# iospear320 register map
Registers are 32-bit, access not given, no defined reset value unless marked. A register's access mark holds for its fields unless they carry their own. Addresses are absolute; registers are grouped by the start of their names; [hi:lo] are bit positions; {n}, {i} and the like mark numbered series.

## MAC
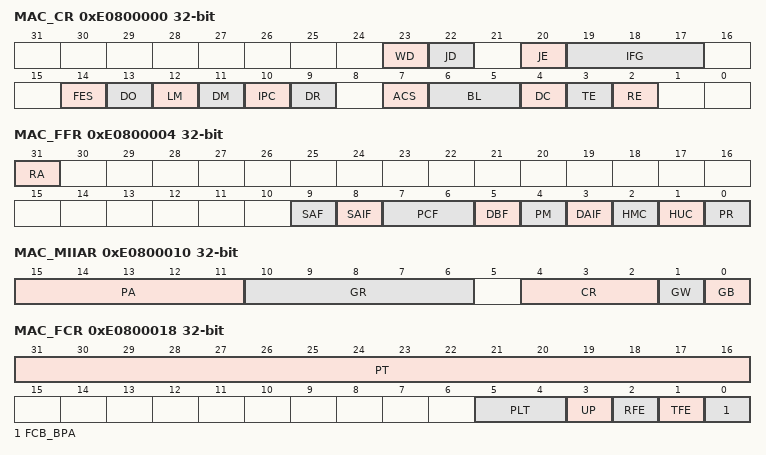
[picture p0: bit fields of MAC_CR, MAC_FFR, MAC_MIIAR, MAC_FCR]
0xE0800000 MAC_CR
  [23] WD, [22] JD, [20] JE, [19:17] IFG, [14] FES, [13] DO, [12] LM, [11] DM, [10] IPC, [9] DR, [7] ACS, [6:5] BL, [4] DC, [3] TE, [2] RE
0xE0800004 MAC_FFR
  [31] RA, [9] SAF, [8] SAIF, [7:6] PCF, [5] DBF, [4] PM, [3] DAIF, [2] HMC, [1] HUC, [0] PR
0xE0800008 MAC_HTHR
0xE080000C MAC_HTLR
0xE0800010 MAC_MIIAR
  [15:11] PA, [10:6] GR, [4:2] CR, [1] GW, [0] GB
0xE0800014 MAC_MIIDR
  [15:0] GD
0xE0800018 MAC_FCR
  [31:16] PT, [5:4] PLT, [3] UP, [2] RFE, [1] TFE, [0] FCB_BPA
0xE080001C MAC_VLANTR
  [15:0] VL
0xE0800020 MAC_VR
  [7:0] VER
0xE0800028 MAC_PTWUFFR
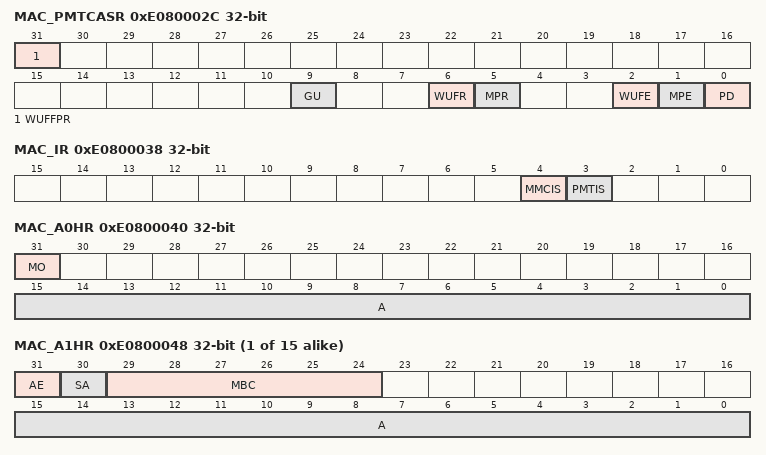
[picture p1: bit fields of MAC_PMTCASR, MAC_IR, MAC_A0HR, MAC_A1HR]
0xE080002C MAC_PMTCASR
  [31] WUFFPR, [9] GU, [6] WUFR, [5] MPR, [2] WUFE, [1] MPE, [0] PD
0xE0800038 MAC_IR
  [4] MMCIS, [3] PMTIS
0xE080003C MAC_IMR
  [3] PMTIM
0xE0800040 MAC_A0HR
  [31] MO, [15:0] A
{0xE0800044+8i} MAC_A{i}LR (i=0..15)
{0xE0800040+8i} MAC_A{i}HR (i=1..15)
  [31] AE, [30] SA, [29:24] MBC, [15:0] A
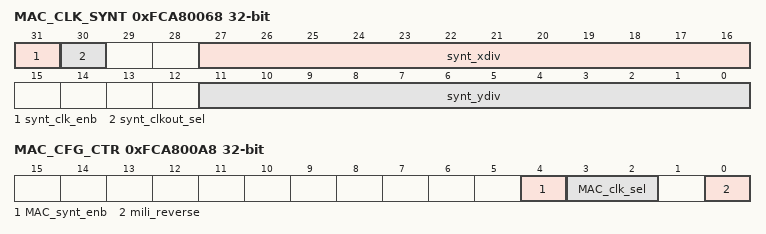
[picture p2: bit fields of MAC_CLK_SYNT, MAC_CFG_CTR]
0xFCA80068 MAC_CLK_SYNT
  [31] synt_clk_enb, [30] synt_clkout_sel, [27:16] synt_xdiv, [11:0] synt_ydiv
0xFCA800A8 MAC_CFG_CTR
  [4] MAC_synt_enb, [3:2] MAC_clk_sel, [0] mili_reverse

## DMA
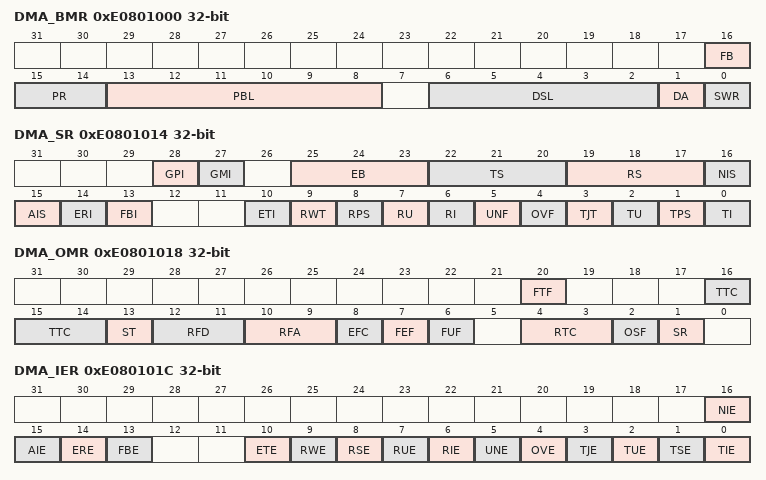
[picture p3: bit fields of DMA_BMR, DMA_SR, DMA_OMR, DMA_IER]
0xE0801000 DMA_BMR
  [16] FB, [15:14] PR, [13:8] PBL, [6:2] DSL, [1] DA, [0] SWR
0xE0801004 DMA_TPDR
0xE0801008 DMA_RPDR
0xE080100C DMA_RDLAR
0xE0801010 DMA_TDLAR
0xE0801014 DMA_SR
  [28] GPI, [27] GMI, [25:23] EB, [22:20] TS, [19:17] RS, [16] NIS, [15] AIS, [14] ERI, [13] FBI, [10] ETI, [9] RWT, [8] RPS, [7] RU, [6] RI, [5] UNF, [4] OVF, [3] TJT, [2] TU, [1] TPS, [0] TI
0xE0801018 DMA_OMR
  [20] FTF, [16:14] TTC, [13] ST, [12:11] RFD, [10:9] RFA, [8] EFC, [7] FEF, [6] FUF, [4:3] RTC, [2] OSF, [1] SR
0xE080101C DMA_IER
  [16] NIE, [15] AIE, [14] ERE, [13] FBE, [10] ETE, [9] RWE, [8] RSE, [7] RUE, [6] RIE, [5] UNE, [4] OVE, [3] TJE, [2] TUE, [1] TSE, [0] TIE
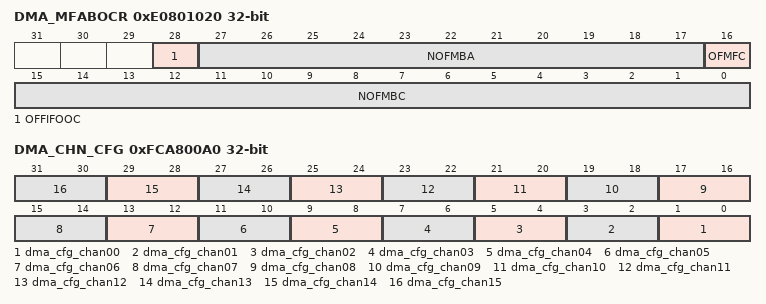
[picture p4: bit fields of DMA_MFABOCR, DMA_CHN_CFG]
0xE0801020 DMA_MFABOCR
  [28] OFFIFOOC, [27:17] NOFMBA, [16] OFMFC, [15:0] NOFMBC
0xE0801048 DMA_CHTDR
0xE080104C DMA_CHRDR
0xE0801050 DMA_CHTBAR
0xE0801054 DMA_CHRBAR
0xFCA800A0 DMA_CHN_CFG
  [2n+1:2n] dma_cfg_chan{n:02} (n=0..15)

## USB2
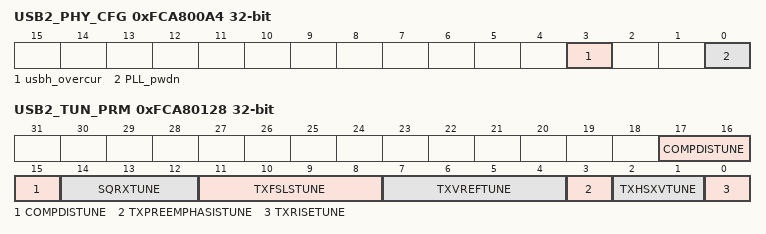
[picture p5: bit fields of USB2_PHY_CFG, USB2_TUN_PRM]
0xFCA800A4 USB2_PHY_CFG
  [3] usbh_overcur, [0] PLL_pwdn
0xFCA80128 USB2_TUN_PRM
  [17:15] COMPDISTUNE, [14:12] SQRXTUNE, [11:8] TXFSLSTUNE, [7:4] TXVREFTUNE, [3] TXPREEMPHASISTUNE, [2:1] TXHSXVTUNE, [0] TXRISETUNE

## PRC1
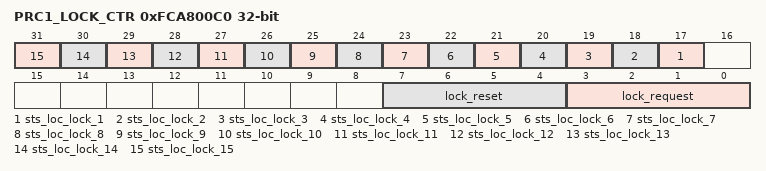
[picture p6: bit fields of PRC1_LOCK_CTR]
0xFCA800C0 PRC1_LOCK_CTR
  [n+16] sts_loc_lock_{n} (n=1..15), [7:4] lock_reset, [3:0] lock_request
0xFCA800D0 PRC1_IRQ_CTR
  [16] int2_req_prc1_1

## PRC2
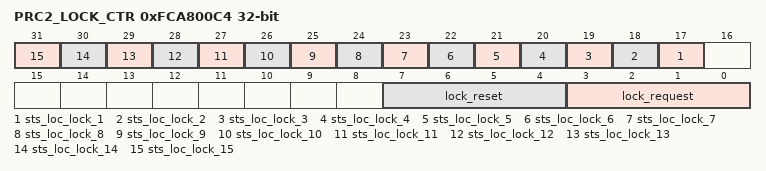
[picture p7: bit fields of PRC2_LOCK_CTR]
0xFCA800C4 PRC2_LOCK_CTR
  [n+16] sts_loc_lock_{n} (n=1..15), [7:4] lock_reset, [3:0] lock_request
0xFCA800D4 PRC2_IRQ_CTR
  [16] int2_req_prc1_1

## BIST1
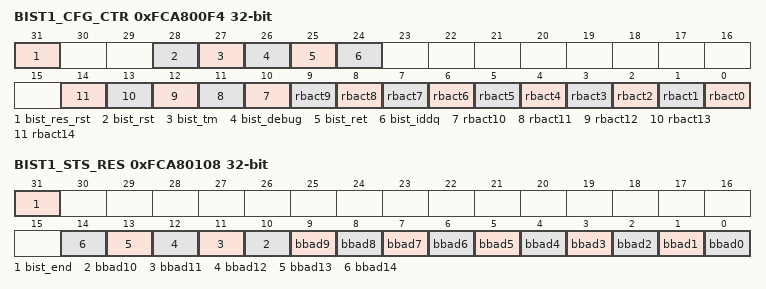
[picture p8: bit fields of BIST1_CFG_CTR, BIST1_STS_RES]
0xFCA800F4 BIST1_CFG_CTR
  [31] bist_res_rst, [28] bist_rst, [27] bist_tm, [26] bist_debug, [25] bist_ret, [24] bist_iddq, [n] rbact{n} (n=0..14)
0xFCA80108 BIST1_STS_RES
  [31] bist_end, [n] bbad{n} (n=0..14)

## BIST2
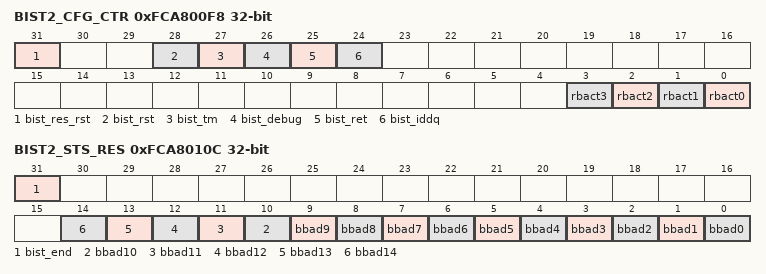
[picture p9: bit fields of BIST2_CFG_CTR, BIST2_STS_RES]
0xFCA800F8 BIST2_CFG_CTR
  [31] bist_res_rst, [28] bist_rst, [27] bist_tm, [26] bist_debug, [25] bist_ret, [24] bist_iddq, [n] rbact{n} (n=0..3)
0xFCA8010C BIST2_STS_RES
  [31] bist_end, [n] bbad{n} (n=0..14)

## BIST3
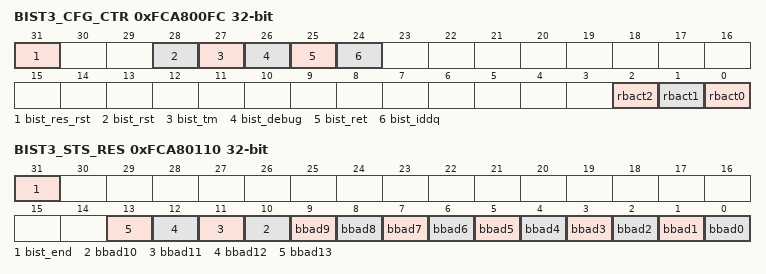
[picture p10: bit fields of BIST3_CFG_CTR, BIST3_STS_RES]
0xFCA800FC BIST3_CFG_CTR
  [31] bist_res_rst, [28] bist_rst, [27] bist_tm, [26] bist_debug, [25] bist_ret, [24] bist_iddq, [2] rbact2, [1] rbact1, [0] rbact0
0xFCA80110 BIST3_STS_RES
  [31] bist_end, [n] bbad{n} (n=0..13)

## BIST4
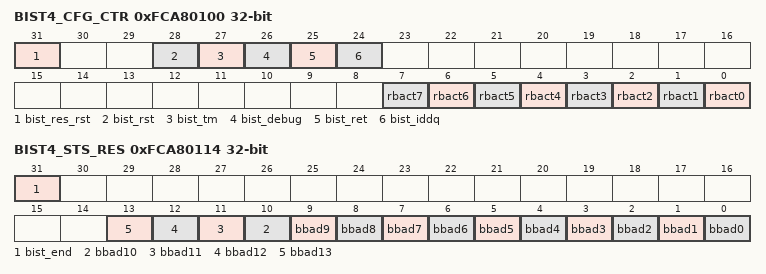
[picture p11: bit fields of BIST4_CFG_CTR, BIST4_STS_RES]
0xFCA80100 BIST4_CFG_CTR
  [31] bist_res_rst, [28] bist_rst, [27] bist_tm, [26] bist_debug, [25] bist_ret, [24] bist_iddq, [n] rbact{n} (n=0..7)
0xFCA80114 BIST4_STS_RES
  [31] bist_end, [n] bbad{n} (n=0..13)
